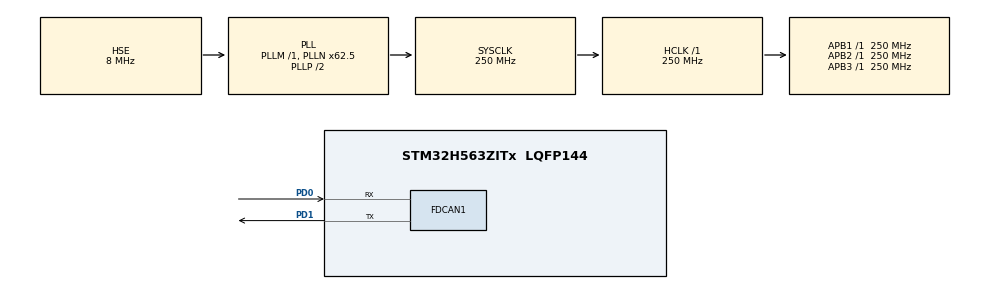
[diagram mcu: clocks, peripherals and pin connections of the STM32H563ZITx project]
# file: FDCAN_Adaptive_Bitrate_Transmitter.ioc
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CORTEX_M33_NS.userName=CORTEX_M33
FDCAN1.AutoRetransmission=DISABLE
FDCAN1.CalculateBaudRateNominal=1000000
FDCAN1.CalculateTimeBitNominal=1000
FDCAN1.CalculateTimeQuantumNominal=4.0
FDCAN1.NominalPrescaler=1
FDCAN1.NominalSyncJumpWidth=62
FDCAN1.NominalTimeSeg1=187
FDCAN1.NominalTimeSeg2=62
FDCAN1.StdFiltersNbr=1
FDCAN1.TransmitPause=ENABLE
Mcu.Family=STM32H5
Mcu.Name=STM32H563ZITx
Mcu.Package=LQFP144
NVIC.PriorityGroup=NVIC_PRIORITYGROUP_4
PD0.Mode=FDCAN_Activate
PD0.Signal=FDCAN1_RX
PD1.Mode=FDCAN_Activate
PD1.Signal=FDCAN1_TX
PH0-OSC_IN(PH0).Mode=HSE-DIG-External-Clock-Source
PH0-OSC_IN(PH0).Signal=RCC_OSC_IN
ProjectManager.HeapSize=0x200
ProjectManager.StackSize=0x400
ProjectManager.TargetToolchain=EWARM V9.20
RCC.ADCFreq_Value=250000000
RCC.AHBFreq_Value=250000000
RCC.APB1Freq_Value=250000000
RCC.APB1TimFreq_Value=250000000
RCC.APB2Freq_Value=250000000
RCC.APB2TimFreq_Value=250000000
RCC.APB3Freq_Value=250000000
RCC.CSI_VALUE=4000000
RCC.CortexFreq_Value=250000000
RCC.EPOD_VALUE=8000000
RCC.FDCANClockSelection=RCC_FDCANCLKSOURCE_PLL1Q
RCC.HCLKFreq_Value=250000000
RCC.HSE_VALUE=8000000
RCC.HSI48_VALUE=48000000
RCC.HSI_VALUE=64000000
RCC.LSE_VALUE=32768
RCC.LSIRC_VALUE=32000
RCC.PLLFRACN=4096
RCC.PLLN=62
RCC.PLLSourceVirtual=RCC_PLL1_SOURCE_HSE
RCC.SYSCLKFreq_VALUE=250000000
RCC.SYSCLKSource=RCC_SYSCLKSOURCE_PLLCLK
RCC.USBFreq_Value=48000000
RCC.VCOOutputFreq_Value=500000000
VP_BOOTPATH_VS_BOOTPATH.Mode=BP_Activate
VP_ICACHE_VS_ICACHE.Mode=DefaultMode
VP_PWR_VS_SECSignals.Mode=Security/Privilege
board=custom

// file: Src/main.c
/* USER CODE BEGIN Header */
/**
  ******************************************************************************
  * @file    FDCAN/FDCAN_Adaptive_Bitrate_Transmitter/Src/main.c
  * @author  MCD Application Team
  * @brief   This sample code shows how to configure the FDCAN to adapt to
  *          different CAN bit rates using restricted mode.
  ******************************************************************************
  * @attention
  *
  * Copyright (c) 2023 STMicroelectronics.
  * All rights reserved.
  *
  * This software is licensed under terms that can be found in the LICENSE file
  * in the root directory of this software component.
  * If no LICENSE file comes with this software, it is provided AS-IS.
  *
  ******************************************************************************
  */
/* USER CODE END Header */
#include "main.h"

/* USER CODE BEGIN PD */
#define TX_TIMEOUT               (1000U)   /* Transmission timeout in ms   */
#define TX_ID                    (0x444)   /* TX CAN message identifier    */
#define RX_ID                    (0x321)   /* RX CAN message identifier    */
#define NB_MSG_TO_RECEIVE        (1U)      /* Number of message to receive */

/* USER CODE END PD */

/* USER CODE BEGIN PM */
#define COUNTOF(BUFFER) (sizeof((BUFFER)) / sizeof(*(BUFFER)))
/* USER CODE END PM */

FDCAN_HandleTypeDef hfdcan1;

/* USER CODE BEGIN PV */
FDCAN_RxHeaderTypeDef rxHeader;
uint8_t               rxData[8U];
static const uint8_t  txData[]         = {0x10, 0x32, 0x54, 0x76, 0x98, 0x00, 0x11, 0x22};
static const uint8_t  expectedRxData[] = {0xFF, 0x00, 0xFF, 0x00, 0xFF, 0x00, 0xFF, 0x00};

/* USER CODE END PV */

void SystemClock_Config(void);
static void MX_GPIO_Init(void);
static void MX_FDCAN1_Init(void);
static void MX_ICACHE_Init(void);
/* USER CODE BEGIN PFP */
static uint32_t BufferCmp8b(const uint8_t *pBuffer1, const uint8_t *pBuffer2, uint16_t BufferLength);

/* USER CODE END PFP */

int main(void)
{
  /* USER CODE BEGIN 1 */
  __IO uint8_t exit_loop = 0U;

  /* STM32H5xx HAL library initialization:
       - Systick timer is configured by default as source of time base, but user
             can eventually implement his proper time base source (a general purpose
             timer for example or other time source), keeping in mind that Time base
             duration should be kept 1ms since PPP_TIMEOUT_VALUEs are defined and
             handled in milliseconds basis.
       - Set NVIC Group Priority to 4
       - Low Level Initialization
     */
  /* USER CODE END 1 */

  /* MCU Configuration--------------------------------------------------------*/

  /* Reset of all peripherals, Initializes the Flash interface and the Systick. */
  HAL_Init();

  /* Configure the system clock */
  SystemClock_Config();

  /* USER CODE BEGIN SysInit */
  /* Configure LED1 and LED3 */
  BSP_LED_Init(LED1);
  BSP_LED_Init(LED3);

  /* USER CODE END SysInit */

  /* Initialize all configured peripherals */
  MX_GPIO_Init();
  MX_FDCAN1_Init();
  MX_ICACHE_Init();
  /* USER CODE BEGIN 2 */

  /*##-1 Configure reception filter #########################################*/

  /* Configure standard ID reception filter to Rx FIFO 0. Only accept ID=RX_ID */
  FDCAN_FilterTypeDef        sFilterConfig;
  sFilterConfig.IdType       = FDCAN_STANDARD_ID;
  sFilterConfig.FilterIndex  = 0U;
  sFilterConfig.FilterType   = FDCAN_FILTER_DUAL;
  sFilterConfig.FilterConfig = FDCAN_FILTER_TO_RXFIFO0;
  sFilterConfig.FilterID1    = RX_ID;
  sFilterConfig.FilterID2    = RX_ID; /* For acceptance, MessageID and FilterID1 must match exactly */
  if (HAL_FDCAN_ConfigFilter(&hfdcan1, &sFilterConfig) != HAL_OK)
  {
    Error_Handler();
  }

  /**
    *  Configure global filter:
    *    - Reject all remote frames with STD and EXT ID
    *    - Reject non matching frames with STD ID and EXT ID
    */
  if (HAL_FDCAN_ConfigGlobalFilter(&hfdcan1,
                                   FDCAN_REJECT, FDCAN_REJECT,
                                   FDCAN_REJECT_REMOTE, FDCAN_REJECT_REMOTE) != HAL_OK)
  {
    Error_Handler();
  }

  /* Start FDCAN controller */
  if (HAL_FDCAN_Start(&hfdcan1) != HAL_OK)
  {
    Error_Handler();
  }

  /*##-2 Send message in a loop until ack message received ##################*/

  while (exit_loop == 0U)
  {
    /**
      * As autoretransmission is disabled, a message previously sent and not acknowledged by the receiver will raise an
      *  error, but will be cleared of the TX FIFO.
      */

    /* Add message to Tx FIFO */
    FDCAN_TxHeaderTypeDef        txHeader;
    txHeader.Identifier          = TX_ID;
    txHeader.IdType              = FDCAN_STANDARD_ID;
    txHeader.TxFrameType         = FDCAN_DATA_FRAME;
    txHeader.DataLength          = FDCAN_DLC_BYTES_8;
    txHeader.ErrorStateIndicator = FDCAN_ESI_ACTIVE;
    txHeader.BitRateSwitch       = FDCAN_BRS_OFF;
    txHeader.FDFormat            = FDCAN_CLASSIC_CAN;
    txHeader.TxEventFifoControl  = FDCAN_STORE_TX_EVENTS;
    txHeader.MessageMarker       = 0U;
    if (HAL_FDCAN_AddMessageToTxFifoQ(&hfdcan1, &txHeader, txData) != HAL_OK)
    {
      Error_Handler();
    }

    /**
      * From this point, the TX message will be sent, and there are two possible outcomes:
      * - The receiver was configured at the right bit rate, received the message, and acknowledged it.
      * - The receiver was not configured at the right bit rate did not acknowledge the message, and caused
      *   an error to be raised by the transmitter.
      * In this example, the error will be ignored.
      */

    /* Check if the ack message was received */
    if (HAL_FDCAN_GetRxFifoFillLevel(&hfdcan1, FDCAN_RX_FIFO0) >= NB_MSG_TO_RECEIVE)
    {
      /* Retrieve Rx message from RX FIFO0 */
      if (HAL_FDCAN_GetRxMessage(&hfdcan1, FDCAN_RX_FIFO0, &rxHeader, rxData) != HAL_OK)
      {
        Error_Handler();
      }

      /* Compare received RX message to expected data */
      if ((rxHeader.Identifier == RX_ID) &&
          (rxHeader.IdType     == FDCAN_STANDARD_ID) &&
          (rxHeader.DataLength == FDCAN_DLC_BYTES_8) &&
          (BufferCmp8b(expectedRxData, rxData, COUNTOF(rxData)) == 0U))
      {
        /* Message was received and data is as expected */
        /* Stop sending message */
        exit_loop = 1U;
      }
    }

    /* Delay before next loop */
    HAL_Delay(20U);
  }

  /* Execution success. Turn ON LED1 */
  BSP_LED_On(LED1);

  /* USER CODE END 2 */

  /* Infinite loop */
  while (1)
  {

  }
}

void SystemClock_Config(void)
{
  RCC_OscInitTypeDef RCC_OscInitStruct = {0};
  RCC_ClkInitTypeDef RCC_ClkInitStruct = {0};

  /** Configure the main internal regulator output voltage
  */
  __HAL_PWR_VOLTAGESCALING_CONFIG(PWR_REGULATOR_VOLTAGE_SCALE0);

  while(!__HAL_PWR_GET_FLAG(PWR_FLAG_VOSRDY)) {}

  /** Initializes the RCC Oscillators according to the specified parameters
  * in the RCC_OscInitTypeDef structure.
  */
  RCC_OscInitStruct.OscillatorType = RCC_OSCILLATORTYPE_HSE;
  RCC_OscInitStruct.HSEState = RCC_HSE_BYPASS_DIGITAL;
  RCC_OscInitStruct.PLL.PLLState = RCC_PLL_ON;
  RCC_OscInitStruct.PLL.PLLSource = RCC_PLL1_SOURCE_HSE;
  RCC_OscInitStruct.PLL.PLLM = 1;
  RCC_OscInitStruct.PLL.PLLN = 62;
  RCC_OscInitStruct.PLL.PLLP = 2;
  RCC_OscInitStruct.PLL.PLLQ = 2;
  RCC_OscInitStruct.PLL.PLLR = 2;
  RCC_OscInitStruct.PLL.PLLRGE = RCC_PLL1_VCIRANGE_3;
  RCC_OscInitStruct.PLL.PLLVCOSEL = RCC_PLL1_VCORANGE_WIDE;
  RCC_OscInitStruct.PLL.PLLFRACN = 4096;
  if (HAL_RCC_OscConfig(&RCC_OscInitStruct) != HAL_OK)
  {
    Error_Handler();
  }

  /** Initializes the CPU, AHB and APB buses clocks
  */
  RCC_ClkInitStruct.ClockType = RCC_CLOCKTYPE_HCLK|RCC_CLOCKTYPE_SYSCLK
                              |RCC_CLOCKTYPE_PCLK1|RCC_CLOCKTYPE_PCLK2
                              |RCC_CLOCKTYPE_PCLK3;
  RCC_ClkInitStruct.SYSCLKSource = RCC_SYSCLKSOURCE_PLLCLK;
  RCC_ClkInitStruct.AHBCLKDivider = RCC_SYSCLK_DIV1;
  RCC_ClkInitStruct.APB1CLKDivider = RCC_HCLK_DIV1;
  RCC_ClkInitStruct.APB2CLKDivider = RCC_HCLK_DIV1;
  RCC_ClkInitStruct.APB3CLKDivider = RCC_HCLK_DIV1;

  if (HAL_RCC_ClockConfig(&RCC_ClkInitStruct, FLASH_LATENCY_5) != HAL_OK)
  {
    Error_Handler();
  }
}

static void MX_FDCAN1_Init(void)
{

  hfdcan1.Instance = FDCAN1;
  hfdcan1.Init.ClockDivider = FDCAN_CLOCK_DIV1;
  hfdcan1.Init.FrameFormat = FDCAN_FRAME_CLASSIC;
  hfdcan1.Init.Mode = FDCAN_MODE_NORMAL;
  hfdcan1.Init.AutoRetransmission = DISABLE;
  hfdcan1.Init.TransmitPause = ENABLE;
  hfdcan1.Init.ProtocolException = DISABLE;
  hfdcan1.Init.NominalPrescaler = 1;
  hfdcan1.Init.NominalSyncJumpWidth = 62;
  hfdcan1.Init.NominalTimeSeg1 = 187;
  hfdcan1.Init.NominalTimeSeg2 = 62;
  hfdcan1.Init.DataPrescaler = 1;
  hfdcan1.Init.DataSyncJumpWidth = 1;
  hfdcan1.Init.DataTimeSeg1 = 1;
  hfdcan1.Init.DataTimeSeg2 = 1;
  hfdcan1.Init.StdFiltersNbr = 1;
  hfdcan1.Init.ExtFiltersNbr = 0;
  hfdcan1.Init.TxFifoQueueMode = FDCAN_TX_FIFO_OPERATION;
  if (HAL_FDCAN_Init(&hfdcan1) != HAL_OK)
  {
    Error_Handler();
  }

}

static void MX_ICACHE_Init(void)
{

  /** Enable instruction cache (default 2-ways set associative cache)
  */
  if (HAL_ICACHE_Enable() != HAL_OK)
  {
    Error_Handler();
  }

}

static void MX_GPIO_Init(void)
{

  /* GPIO Ports Clock Enable */
  __HAL_RCC_GPIOH_CLK_ENABLE();
  __HAL_RCC_GPIOD_CLK_ENABLE();

}

/* USER CODE BEGIN 4 */

/**
  * @brief  Compares two buffers.
  * @param  pBuffer1 buffer to be compared.
  * @param  pBuffer2 buffer to be compared.
  * @param  BufferLength: buffer's length.
  * @retval 0: pBuffer1 is identical to pBuffer2
  * @retval 1: pBuffer1 differs from pBuffer2
  */
static uint32_t BufferCmp8b(const uint8_t *pBuffer1, const uint8_t *pBuffer2, uint16_t BufferLength)
{
  while (BufferLength--)
  {
    if (*pBuffer1 != *pBuffer2)
    {
      return 1U;
    }

    pBuffer1++;
    pBuffer2++;
  }
  return 0U;
}
/* USER CODE END 4 */

void Error_Handler(void)
{
  /* USER CODE BEGIN Error_Handler_Debug */
  /* User can add his own implementation to report the HAL error return state */

  while (1)
  {
    /* Toggle LED3 on */
    BSP_LED_Toggle(LED3);

    /* 1s delay */
    HAL_Delay(1000U);
  }
  /* USER CODE END Error_Handler_Debug */
}
